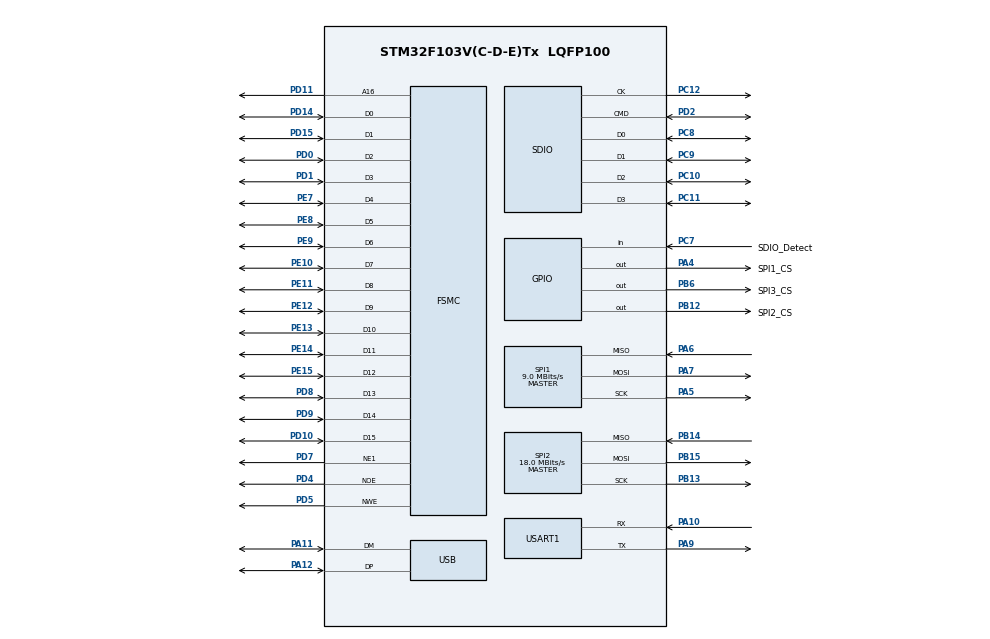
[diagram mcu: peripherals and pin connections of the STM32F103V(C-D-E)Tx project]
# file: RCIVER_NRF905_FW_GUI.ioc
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Mcu.Family=STM32F1
Mcu.Name=STM32F103V(C-D-E)Tx
Mcu.Package=LQFP100
NVIC.PriorityGroup=NVIC_PRIORITYGROUP_4
NVIC.USB_LP_CAN1_RX0_IRQn=true\:0\:0\:false\:false\:true\:false\:true
OSC_IN.Mode=HSE-External-Oscillator
OSC_IN.Signal=RCC_OSC_IN
OSC_OUT.Mode=HSE-External-Oscillator
OSC_OUT.Signal=RCC_OSC_OUT
PA10.Mode=Asynchronous
PA10.Signal=USART1_RX
PA11.Mode=Device
PA11.Signal=USB_DM
PA12.Mode=Device
PA12.Signal=USB_DP
PA13.Mode=Serial_Wire
PA13.Signal=SYS_JTMS-SWDIO
PA14.Mode=Serial_Wire
PA14.Signal=SYS_JTCK-SWCLK
PA4.GPIO_Label=SPI1_CS
PA4.Signal=GPIO_Output
PA5.Mode=Full_Duplex_Master
PA5.Signal=SPI1_SCK
PA6.Mode=Full_Duplex_Master
PA6.Signal=SPI1_MISO
PA7.Mode=Full_Duplex_Master
PA7.Signal=SPI1_MOSI
PA9.Mode=Asynchronous
PA9.Signal=USART1_TX
PB12.GPIO_Label=SPI2_CS
PB12.Signal=GPIO_Output
PB13.Mode=Full_Duplex_Master
PB13.Signal=SPI2_SCK
PB14.Mode=Full_Duplex_Master
PB14.Signal=SPI2_MISO
PB15.Mode=Full_Duplex_Master
PB15.Signal=SPI2_MOSI
PB6.GPIO_Label=SPI3_CS
PB6.Signal=GPIO_Output
PC10.Mode=SD_4_bits_Wide_bus
PC10.Signal=SDIO_D2
PC11.Mode=SD_4_bits_Wide_bus
PC11.Signal=SDIO_D3
PC12.Mode=SD_4_bits_Wide_bus
PC12.Signal=SDIO_CK
PC14-OSC32_IN.Mode=LSE-External-Oscillator
PC14-OSC32_IN.Signal=RCC_OSC32_IN
PC15-OSC32_OUT.Mode=LSE-External-Oscillator
PC15-OSC32_OUT.Signal=RCC_OSC32_OUT
PC7.GPIO_Label=SDIO_Detect
PC7.Signal=GPIO_Input
PC8.Mode=SD_4_bits_Wide_bus
PC8.Signal=SDIO_D0
PC9.Mode=SD_4_bits_Wide_bus
PC9.Signal=SDIO_D1
PD0.Mode=16b-d1
PD0.Signal=FSMC_D2
PD1.Mode=16b-d1
PD1.Signal=FSMC_D3
PD10.Mode=16b-d1
PD10.Signal=FSMC_D15
PD11.Mode=A16_1
PD11.Signal=FSMC_A16
PD14.Mode=16b-d1
PD14.Signal=FSMC_D0
PD15.Mode=16b-d1
PD15.Signal=FSMC_D1
PD2.Mode=SD_4_bits_Wide_bus
PD2.Signal=SDIO_CMD
PD4.Mode=Lcd1
PD4.Signal=FSMC_NOE
PD5.Mode=Lcd1
PD5.Signal=FSMC_NWE
PD7.Mode=NorPsramChipSelect1_1
PD7.Signal=FSMC_NE1
PD8.Mode=16b-d1
PD8.Signal=FSMC_D13
PD9.Mode=16b-d1
PD9.Signal=FSMC_D14
PE10.Mode=16b-d1
PE10.Signal=FSMC_D7
PE11.Mode=16b-d1
PE11.Signal=FSMC_D8
PE12.Mode=16b-d1
PE12.Signal=FSMC_D9
PE13.Mode=16b-d1
PE13.Signal=FSMC_D10
PE14.Mode=16b-d1
PE14.Signal=FSMC_D11
PE15.Mode=16b-d1
PE15.Signal=FSMC_D12
PE7.Mode=16b-d1
PE7.Signal=FSMC_D4
PE8.Mode=16b-d1
PE8.Signal=FSMC_D5
PE9.Mode=16b-d1
PE9.Signal=FSMC_D6
ProjectManager.HeapSize=0x200
ProjectManager.StackSize=0x400
ProjectManager.TargetToolchain=Makefile
RCC.AHBFreq_Value=72000000
RCC.APB1CLKDivider=RCC_HCLK_DIV2
RCC.APB1Freq_Value=36000000
RCC.APB1TimFreq_Value=72000000
RCC.APB2Freq_Value=72000000
RCC.APB2TimFreq_Value=72000000
RCC.HCLKFreq_Value=72000000
RCC.PLLMUL=RCC_PLL_MUL9
RCC.RTCClockSelection=RCC_RTCCLKSOURCE_LSE
RCC.SYSCLKFreq_VALUE=72000000
RCC.SYSCLKSource=RCC_SYSCLKSOURCE_PLLCLK
RCC.USBFreq_Value=48000000
RCC.USBPrescaler=RCC_USBCLKSOURCE_PLL_DIV1_5
SPI1.BaudRatePrescaler=SPI_BAUDRATEPRESCALER_8
SPI1.CalculateBaudRate=9.0 MBits/s
SPI1.Direction=SPI_DIRECTION_2LINES
SPI1.Mode=SPI_MODE_MASTER
SPI1.VirtualType=VM_MASTER
SPI2.CalculateBaudRate=18.0 MBits/s
SPI2.Direction=SPI_DIRECTION_2LINES
SPI2.Mode=SPI_MODE_MASTER
SPI2.VirtualType=VM_MASTER
USART1.VirtualMode=VM_ASYNC
USB_DEVICE.CLASS_NAME_FS=CDC
USB_DEVICE.VirtualMode=Cdc
USB_DEVICE.VirtualModeFS=Cdc_FS
VP_RTC_VS_RTC_Activate.Mode=RTC_Enabled
VP_USB_DEVICE_VS_USB_DEVICE_CDC_FS.Mode=CDC_FS
board=custom

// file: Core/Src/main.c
/* USER CODE BEGIN Header */
/**
  ******************************************************************************
  * @file           : main.c
  * @brief          : Main program body
  ******************************************************************************
  * @attention
  *
  * <h2><center>&copy; Copyright (c) 2021 STMicroelectronics.
  * All rights reserved.</center></h2>
  *
  * This software component is licensed by ST under Ultimate Liberty license
  * SLA0044, the "License"; You may not use this file except in compliance with
  * the License. You may obtain a copy of the License at:
  *                             www.st.com/SLA0044
  *
  ******************************************************************************
  */
/* USER CODE END Header */
#include "main.h"
#include "rtc.h"
#include "sdio.h"
#include "spi.h"
#include "usart.h"
#include "usb_device.h"
#include "gpio.h"
#include "fsmc.h"

void SystemClock_Config(void);

int main(void)
{

  /* MCU Configuration--------------------------------------------------------*/

  /* Reset of all peripherals, Initializes the Flash interface and the Systick. */
  HAL_Init();

  /* Configure the system clock */
  SystemClock_Config();

  /* Initialize all configured peripherals */
  MX_GPIO_Init();
  MX_FSMC_Init();
  MX_RTC_Init();
  MX_SDIO_SD_Init();
  MX_SPI1_Init();
  MX_USART1_UART_Init();
  MX_USB_DEVICE_Init();
  MX_SPI2_Init();

  /* Infinite loop */
  while (1)
  {

  }
}

void SystemClock_Config(void)
{
  LL_FLASH_SetLatency(LL_FLASH_LATENCY_2);
  while(LL_FLASH_GetLatency()!= LL_FLASH_LATENCY_2)
  {
  }
  LL_RCC_HSE_Enable();

   /* Wait till HSE is ready */
  while(LL_RCC_HSE_IsReady() != 1)
  {

  }
  LL_PWR_EnableBkUpAccess();
  LL_RCC_LSE_Enable();

   /* Wait till LSE is ready */
  while(LL_RCC_LSE_IsReady() != 1)
  {

  }
  if(LL_RCC_GetRTCClockSource() != LL_RCC_RTC_CLKSOURCE_LSE)
  {
    LL_RCC_ForceBackupDomainReset();
    LL_RCC_ReleaseBackupDomainReset();
    LL_RCC_SetRTCClockSource(LL_RCC_RTC_CLKSOURCE_LSE);
  }
  LL_RCC_EnableRTC();
  LL_RCC_PLL_ConfigDomain_SYS(LL_RCC_PLLSOURCE_HSE_DIV_1, LL_RCC_PLL_MUL_9);
  LL_RCC_PLL_Enable();

   /* Wait till PLL is ready */
  while(LL_RCC_PLL_IsReady() != 1)
  {

  }
  LL_RCC_SetAHBPrescaler(LL_RCC_SYSCLK_DIV_1);
  LL_RCC_SetAPB1Prescaler(LL_RCC_APB1_DIV_2);
  LL_RCC_SetAPB2Prescaler(LL_RCC_APB2_DIV_1);
  LL_RCC_SetSysClkSource(LL_RCC_SYS_CLKSOURCE_PLL);

   /* Wait till System clock is ready */
  while(LL_RCC_GetSysClkSource() != LL_RCC_SYS_CLKSOURCE_STATUS_PLL)
  {

  }
  LL_SetSystemCoreClock(72000000);

   /* Update the time base */
  if (HAL_InitTick (TICK_INT_PRIORITY) != HAL_OK)
  {
    Error_Handler();
  }
  LL_RCC_SetUSBClockSource(LL_RCC_USB_CLKSOURCE_PLL_DIV_1_5);
}

/* USER CODE BEGIN 4 */
void LCD_CmdWrite(const uint16_t Command)
{
	LCD->LCD_REG = Command;
}

void LCD_DataWrite(const uint16_t Data)
{
	LCD->LCD_RAM = Data;
}

void LCD_WriteReg(const uint8_t LCD_Reg, const uint16_t LCD_RegValue)
{
	LCD->LCD_REG = LCD_Reg;
	LCD->LCD_RAM = LCD_RegValue;
}
/* USER CODE END 4 */

void Error_Handler(void)
{
  __disable_irq();
  while (1)
  {
  }
}

/************************ (C) COPYRIGHT STMicroelectronics *****END OF FILE****/
